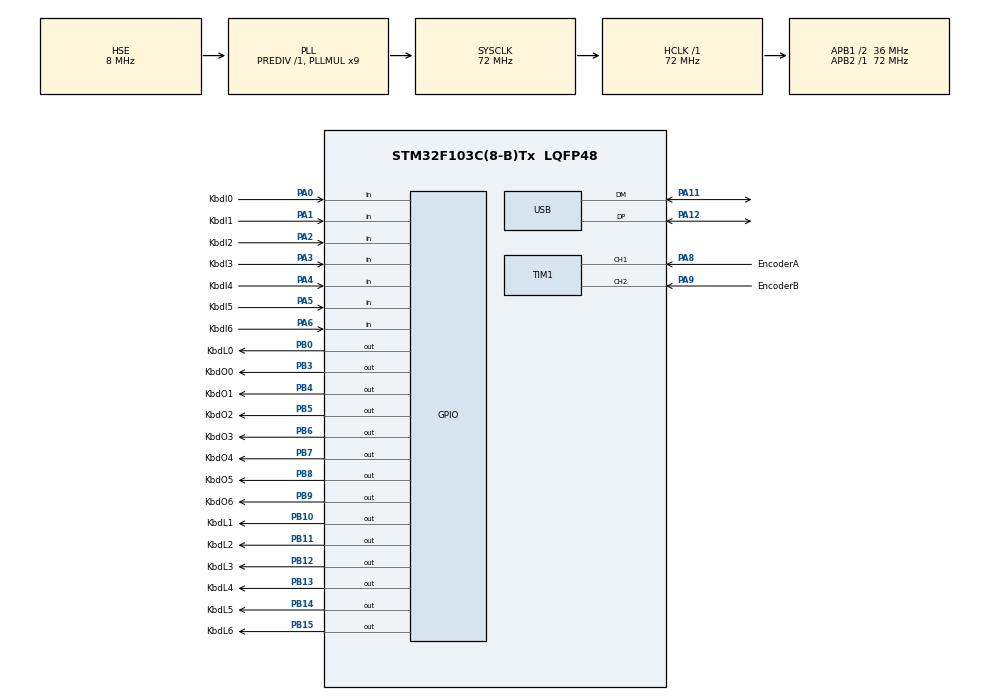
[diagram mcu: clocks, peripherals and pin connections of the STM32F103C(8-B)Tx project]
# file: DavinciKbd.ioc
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Mcu.Family=STM32F1
Mcu.Name=STM32F103C(8-B)Tx
Mcu.Package=LQFP48
NVIC.PriorityGroup=NVIC_PRIORITYGROUP_4
NVIC.TIM2_IRQn=true\:0\:0\:false\:false\:true\:true\:true
NVIC.USB_LP_CAN1_RX0_IRQn=true\:0\:0\:false\:false\:true\:false\:true
PA0-WKUP.GPIO_Label=KbdI0
PA0-WKUP.GPIO_PuPd=GPIO_PULLUP
PA0-WKUP.Signal=GPIO_Input
PA1.GPIO_Label=KbdI1
PA1.GPIO_PuPd=GPIO_PULLUP
PA1.Signal=GPIO_Input
PA11.Mode=Device
PA11.Signal=USB_DM
PA12.Mode=Device
PA12.Signal=USB_DP
PA13.Mode=Serial_Wire
PA13.Signal=SYS_JTMS-SWDIO
PA14.Mode=Serial_Wire
PA14.Signal=SYS_JTCK-SWCLK
PA2.GPIO_Label=KbdI2
PA2.GPIO_PuPd=GPIO_PULLUP
PA2.Signal=GPIO_Input
PA3.GPIO_Label=KbdI3
PA3.GPIO_PuPd=GPIO_PULLUP
PA3.Signal=GPIO_Input
PA4.GPIO_Label=KbdI4
PA4.GPIO_PuPd=GPIO_PULLUP
PA4.Signal=GPIO_Input
PA5.GPIO_Label=KbdI5
PA5.GPIO_PuPd=GPIO_PULLUP
PA5.Signal=GPIO_Input
PA6.GPIO_Label=KbdI6
PA6.GPIO_PuPd=GPIO_PULLUP
PA6.Signal=GPIO_Input
PA8.GPIO_Label=EncoderA
PA8.GPIO_PuPd=GPIO_PULLUP
PA8.Signal=S_TIM1_CH1
PA9.GPIO_Label=EncoderB
PA9.GPIO_PuPd=GPIO_PULLUP
PA9.Signal=S_TIM1_CH2
PB0.GPIO_Label=KbdL0
PB0.Signal=GPIO_Output
PB10.GPIO_Label=KbdL1
PB10.Signal=GPIO_Output
PB11.GPIO_Label=KbdL2
PB11.Signal=GPIO_Output
PB12.GPIO_Label=KbdL3
PB12.Signal=GPIO_Output
PB13.GPIO_Label=KbdL4
PB13.Signal=GPIO_Output
PB14.GPIO_Label=KbdL5
PB14.Signal=GPIO_Output
PB15.GPIO_Label=KbdL6
PB15.Signal=GPIO_Output
PB3.GPIO_Label=KbdO0
PB3.GPIO_ModeDefaultOutputPP=GPIO_MODE_OUTPUT_OD
PB3.Signal=GPIO_Output
PB4.GPIO_Label=KbdO1
PB4.GPIO_ModeDefaultOutputPP=GPIO_MODE_OUTPUT_OD
PB4.Signal=GPIO_Output
PB5.GPIO_Label=KbdO2
PB5.GPIO_ModeDefaultOutputPP=GPIO_MODE_OUTPUT_OD
PB5.Signal=GPIO_Output
PB6.GPIO_Label=KbdO3
PB6.GPIO_ModeDefaultOutputPP=GPIO_MODE_OUTPUT_OD
PB6.Signal=GPIO_Output
PB7.GPIO_Label=KbdO4
PB7.GPIO_ModeDefaultOutputPP=GPIO_MODE_OUTPUT_OD
PB7.Signal=GPIO_Output
PB8.GPIO_Label=KbdO5
PB8.GPIO_ModeDefaultOutputPP=GPIO_MODE_OUTPUT_OD
PB8.Signal=GPIO_Output
PB9.GPIO_Label=KbdO6
PB9.GPIO_ModeDefaultOutputPP=GPIO_MODE_OUTPUT_OD
PB9.Signal=GPIO_Output
PC14-OSC32_IN.Mode=LSE-External-Oscillator
PC14-OSC32_IN.Signal=RCC_OSC32_IN
PC15-OSC32_OUT.Mode=LSE-External-Oscillator
PC15-OSC32_OUT.Signal=RCC_OSC32_OUT
PD0-OSC_IN.Mode=HSE-External-Oscillator
PD0-OSC_IN.Signal=RCC_OSC_IN
PD1-OSC_OUT.Mode=HSE-External-Oscillator
PD1-OSC_OUT.Signal=RCC_OSC_OUT
ProjectManager.HeapSize=0x200
ProjectManager.StackSize=0x400
ProjectManager.TargetToolchain=STM32CubeIDE
RCC.AHBFreq_Value=72000000
RCC.APB1CLKDivider=RCC_HCLK_DIV2
RCC.APB1Freq_Value=36000000
RCC.APB1TimFreq_Value=72000000
RCC.APB2Freq_Value=72000000
RCC.APB2TimFreq_Value=72000000
RCC.HCLKFreq_Value=72000000
RCC.PLLMUL=RCC_PLL_MUL9
RCC.PLLSourceVirtual=RCC_PLLSOURCE_HSE
RCC.SYSCLKFreq_VALUE=72000000
RCC.SYSCLKSource=RCC_SYSCLKSOURCE_PLLCLK
RCC.USBFreq_Value=48000000
RCC.USBPrescaler=RCC_USBCLKSOURCE_PLL_DIV1_5
SH.S_TIM1_CH1.0=TIM1_CH1,Encoder_Interface
SH.S_TIM1_CH2.0=TIM1_CH2,Encoder_Interface
TIM1.EncoderMode=TIM_ENCODERMODE_TI12
TIM2.ClockDivision=TIM_CLOCKDIVISION_DIV2
TIM2.Period=32000
TIM2.Prescaler=0
USB_DEVICE.CLASS_NAME_FS=CUSTOM_HID
USB_DEVICE.PID_CUSTOMHID_FS=22334 
USB_DEVICE.PRODUCT_STRING_CUSTOMHID_FS=DIY Speed Editor
USB_DEVICE.USBD_CUSTOMHID_OUTREPORT_BUF_SIZE=64
USB_DEVICE.VirtualMode=CustomHid
USB_DEVICE.VirtualModeFS=Custom_Hid_FS
VP_TIM2_VS_ClockSourceINT.Mode=Internal
VP_USB_DEVICE_VS_USB_DEVICE_CUSTOM_HID_FS.Mode=CUSTOM_HID_FS
board=custom

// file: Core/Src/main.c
/* USER CODE BEGIN Header */
/**
  ******************************************************************************
  * @file           : main.c
  * @brief          : Main program body
  ******************************************************************************
  * @attention
  *
  * <h2><center>&copy; Copyright (c) 2021 STMicroelectronics.
  * All rights reserved.</center></h2>
  *
  * This software component is licensed by ST under Ultimate Liberty license
  * SLA0044, the "License"; You may not use this file except in compliance with
  * the License. You may obtain a copy of the License at:
  *                             www.st.com/SLA0044
  *
  ******************************************************************************
  */
/* USER CODE END Header */
#include "main.h"
#include "usb_device.h"

/* USER CODE BEGIN Includes */
#include "kbd_led.h"
#include "usbd_customhid.h"
#include "settings.h"
/* USER CODE END Includes */

TIM_HandleTypeDef htim1;
TIM_HandleTypeDef htim2;

/* USER CODE BEGIN PV */
extern USBD_HandleTypeDef hUsbDeviceFS;
uint8_t reprep[10] = {1,2,3,4,5,6};

/* USER CODE END PV */

void SystemClock_Config(void);
static void MX_GPIO_Init(void);
static void MX_TIM1_Init(void);
static void MX_TIM2_Init(void);

int main(void)
{

  /* MCU Configuration--------------------------------------------------------*/

  /* Reset of all peripherals, Initializes the Flash interface and the Systick. */
  HAL_Init();

  /* Configure the system clock */
  SystemClock_Config();

  /* Initialize all configured peripherals */
  MX_GPIO_Init();
  MX_TIM1_Init();
  MX_USB_DEVICE_Init();
  MX_TIM2_Init();
  /* USER CODE BEGIN 2 */
  InitSettings();
  KbdInit();

  /* USER CODE END 2 */

  /* Infinite loop */
  /* USER CODE BEGIN WHILE */
  while (1)
  {
	  //HAL_Delay(1000);
	  //USBD_CUSTOM_HID_SendReport(&hUsbDeviceFS, reprep, 10);
	  PollKbdJog();
    /* USER CODE END WHILE */

  }
}

void SystemClock_Config(void)
{
  RCC_OscInitTypeDef RCC_OscInitStruct = {0};
  RCC_ClkInitTypeDef RCC_ClkInitStruct = {0};
  RCC_PeriphCLKInitTypeDef PeriphClkInit = {0};

  /** Initializes the RCC Oscillators according to the specified parameters
  * in the RCC_OscInitTypeDef structure.
  */
  RCC_OscInitStruct.OscillatorType = RCC_OSCILLATORTYPE_HSE;
  RCC_OscInitStruct.HSEState = RCC_HSE_ON;
  RCC_OscInitStruct.HSEPredivValue = RCC_HSE_PREDIV_DIV1;
  RCC_OscInitStruct.HSIState = RCC_HSI_ON;
  RCC_OscInitStruct.PLL.PLLState = RCC_PLL_ON;
  RCC_OscInitStruct.PLL.PLLSource = RCC_PLLSOURCE_HSE;
  RCC_OscInitStruct.PLL.PLLMUL = RCC_PLL_MUL9;
  if (HAL_RCC_OscConfig(&RCC_OscInitStruct) != HAL_OK)
  {
    Error_Handler();
  }
  /** Initializes the CPU, AHB and APB buses clocks
  */
  RCC_ClkInitStruct.ClockType = RCC_CLOCKTYPE_HCLK|RCC_CLOCKTYPE_SYSCLK
                              |RCC_CLOCKTYPE_PCLK1|RCC_CLOCKTYPE_PCLK2;
  RCC_ClkInitStruct.SYSCLKSource = RCC_SYSCLKSOURCE_PLLCLK;
  RCC_ClkInitStruct.AHBCLKDivider = RCC_SYSCLK_DIV1;
  RCC_ClkInitStruct.APB1CLKDivider = RCC_HCLK_DIV2;
  RCC_ClkInitStruct.APB2CLKDivider = RCC_HCLK_DIV1;

  if (HAL_RCC_ClockConfig(&RCC_ClkInitStruct, FLASH_LATENCY_2) != HAL_OK)
  {
    Error_Handler();
  }
  PeriphClkInit.PeriphClockSelection = RCC_PERIPHCLK_USB;
  PeriphClkInit.UsbClockSelection = RCC_USBCLKSOURCE_PLL_DIV1_5;
  if (HAL_RCCEx_PeriphCLKConfig(&PeriphClkInit) != HAL_OK)
  {
    Error_Handler();
  }
}

static void MX_TIM1_Init(void)
{

  TIM_Encoder_InitTypeDef sConfig = {0};
  TIM_MasterConfigTypeDef sMasterConfig = {0};

  htim1.Instance = TIM1;
  htim1.Init.Prescaler = 0;
  htim1.Init.CounterMode = TIM_COUNTERMODE_UP;
  htim1.Init.Period = 65535;
  htim1.Init.ClockDivision = TIM_CLOCKDIVISION_DIV1;
  htim1.Init.RepetitionCounter = 0;
  htim1.Init.AutoReloadPreload = TIM_AUTORELOAD_PRELOAD_DISABLE;
  sConfig.EncoderMode = TIM_ENCODERMODE_TI12;
  sConfig.IC1Polarity = TIM_ICPOLARITY_RISING;
  sConfig.IC1Selection = TIM_ICSELECTION_DIRECTTI;
  sConfig.IC1Prescaler = TIM_ICPSC_DIV1;
  sConfig.IC1Filter = 0;
  sConfig.IC2Polarity = TIM_ICPOLARITY_RISING;
  sConfig.IC2Selection = TIM_ICSELECTION_DIRECTTI;
  sConfig.IC2Prescaler = TIM_ICPSC_DIV1;
  sConfig.IC2Filter = 0;
  if (HAL_TIM_Encoder_Init(&htim1, &sConfig) != HAL_OK)
  {
    Error_Handler();
  }
  sMasterConfig.MasterOutputTrigger = TIM_TRGO_RESET;
  sMasterConfig.MasterSlaveMode = TIM_MASTERSLAVEMODE_DISABLE;
  if (HAL_TIMEx_MasterConfigSynchronization(&htim1, &sMasterConfig) != HAL_OK)
  {
    Error_Handler();
  }
  /* USER CODE BEGIN TIM1_Init 2 */
  HAL_TIM_Encoder_Start(&htim1,TIM_CHANNEL_ALL);

  /* USER CODE END TIM1_Init 2 */

}

static void MX_TIM2_Init(void)
{

  TIM_ClockConfigTypeDef sClockSourceConfig = {0};
  TIM_MasterConfigTypeDef sMasterConfig = {0};

  htim2.Instance = TIM2;
  htim2.Init.Prescaler = 0;
  htim2.Init.CounterMode = TIM_COUNTERMODE_UP;
  htim2.Init.Period = 32000;
  htim2.Init.ClockDivision = TIM_CLOCKDIVISION_DIV2;
  htim2.Init.AutoReloadPreload = TIM_AUTORELOAD_PRELOAD_DISABLE;
  if (HAL_TIM_Base_Init(&htim2) != HAL_OK)
  {
    Error_Handler();
  }
  sClockSourceConfig.ClockSource = TIM_CLOCKSOURCE_INTERNAL;
  if (HAL_TIM_ConfigClockSource(&htim2, &sClockSourceConfig) != HAL_OK)
  {
    Error_Handler();
  }
  sMasterConfig.MasterOutputTrigger = TIM_TRGO_RESET;
  sMasterConfig.MasterSlaveMode = TIM_MASTERSLAVEMODE_DISABLE;
  if (HAL_TIMEx_MasterConfigSynchronization(&htim2, &sMasterConfig) != HAL_OK)
  {
    Error_Handler();
  }
  /* USER CODE BEGIN TIM2_Init 2 */
  HAL_TIM_Base_Start_IT(&htim2);

  /* USER CODE END TIM2_Init 2 */

}

static void MX_GPIO_Init(void)
{
  GPIO_InitTypeDef GPIO_InitStruct = {0};

  /* GPIO Ports Clock Enable */
  __HAL_RCC_GPIOC_CLK_ENABLE();
  __HAL_RCC_GPIOD_CLK_ENABLE();
  __HAL_RCC_GPIOA_CLK_ENABLE();
  __HAL_RCC_GPIOB_CLK_ENABLE();

  /*Configure GPIO pin Output Level */
  HAL_GPIO_WritePin(GPIOB, KbdL0_Pin|KbdL1_Pin|KbdL2_Pin|KbdL3_Pin
                          |KbdL4_Pin|KbdL5_Pin|KbdL6_Pin|KbdO0_Pin
                          |KbdO1_Pin|KbdO2_Pin|KbdO3_Pin|KbdO4_Pin
                          |KbdO5_Pin|KbdO6_Pin, GPIO_PIN_RESET);

  /*Configure GPIO pins : KbdI0_Pin KbdI1_Pin KbdI2_Pin KbdI3_Pin
                           KbdI4_Pin KbdI5_Pin KbdI6_Pin */
  GPIO_InitStruct.Pin = KbdI0_Pin|KbdI1_Pin|KbdI2_Pin|KbdI3_Pin
                          |KbdI4_Pin|KbdI5_Pin|KbdI6_Pin;
  GPIO_InitStruct.Mode = GPIO_MODE_INPUT;
  GPIO_InitStruct.Pull = GPIO_PULLUP;
  HAL_GPIO_Init(GPIOA, &GPIO_InitStruct);

  /*Configure GPIO pins : KbdL0_Pin KbdL1_Pin KbdL2_Pin KbdL3_Pin
                           KbdL4_Pin KbdL5_Pin KbdL6_Pin */
  GPIO_InitStruct.Pin = KbdL0_Pin|KbdL1_Pin|KbdL2_Pin|KbdL3_Pin
                          |KbdL4_Pin|KbdL5_Pin|KbdL6_Pin;
  GPIO_InitStruct.Mode = GPIO_MODE_OUTPUT_PP;
  GPIO_InitStruct.Pull = GPIO_NOPULL;
  GPIO_InitStruct.Speed = GPIO_SPEED_FREQ_LOW;
  HAL_GPIO_Init(GPIOB, &GPIO_InitStruct);

  /*Configure GPIO pins : KbdO0_Pin KbdO1_Pin KbdO2_Pin KbdO3_Pin
                           KbdO4_Pin KbdO5_Pin KbdO6_Pin */
  GPIO_InitStruct.Pin = KbdO0_Pin|KbdO1_Pin|KbdO2_Pin|KbdO3_Pin
                          |KbdO4_Pin|KbdO5_Pin|KbdO6_Pin;
  GPIO_InitStruct.Mode = GPIO_MODE_OUTPUT_OD;
  GPIO_InitStruct.Pull = GPIO_NOPULL;
  GPIO_InitStruct.Speed = GPIO_SPEED_FREQ_LOW;
  HAL_GPIO_Init(GPIOB, &GPIO_InitStruct);

}

void Error_Handler(void)
{
  __disable_irq();
  while (1)
  {
  }
}

/************************ (C) COPYRIGHT STMicroelectronics *****END OF FILE****/
